# DMASS_BCDMA_0_DMASS_BCDMA_0_BCDMA_FLOW_48300000h register map
Vendor: Texas Instruments
Peripheral module from a debugger description file (folder am62L).
Registers are 32-bit, read-write, reset 0x0 unless marked. A register's access mark holds for its fields unless they carry their own. Offsets are as the file gives them; lines under a group give offsets from that group; [hi:lo] are bit positions; {n}, {i} and the like mark numbered series; 'fields as' and 'values as' point back to an identical list; <NAME> marks a mode.

## DMASS_BCDMA_0_BCDMA_FLOW
0x00 DMASS_BCDMA_0_BCDMA_FLOW_FLOW_resrc_j reset 0x80000000 — The Flow Resource Register contains the alias to real time register. A write to this register will reset the associated ring to clear the occupancies and reset the pointers.
  [31] ALIAS — Allow the Ring Address and Size Registers to appear in the Ring Real-Time region to allow for the ring to be placed and sized by the user process. Reset Source: rst_mod_g_rst_n
0x40 DMASS_BCDMA_0_BCDMA_FLOW_FLOW_ba_lo_j — The Ring Base Address Lo Register contains the 32 LSBs of the base address for the ring which is used to hand off pending work for the channel from the Host. The base address must be aligned to 0x8. A write to this register will reset the associated ring to clear the occupancies and reset the pointers.
  [31:0] ADDR_LO — Ring base address (LSBs) Reset Source: rst_mod_g_rst_n
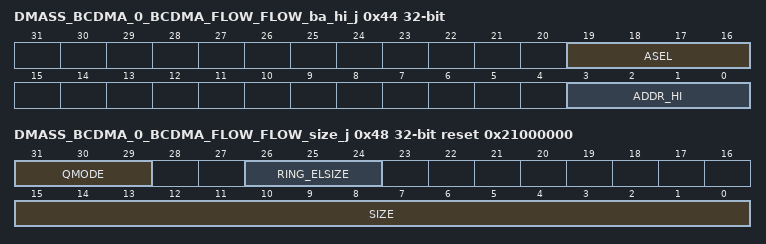
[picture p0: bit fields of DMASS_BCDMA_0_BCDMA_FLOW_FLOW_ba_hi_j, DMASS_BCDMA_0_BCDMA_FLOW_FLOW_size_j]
0x44 DMASS_BCDMA_0_BCDMA_FLOW_FLOW_ba_hi_j — The Ring Base Address Hi Register contains the 16 MSBs of the base address for the ring which is used to hand off pending work for the channel from the Host. The base address must be aligned to 0x8. A write to this register will reset the associated ring to clear the occupancies and reset the pointers.
  [19:16] ASEL — Ring base address select Reset Source: rst_mod_g_rst_n
  [3:0] ADDR_HI — Ring base address (MSBs) Reset Source: rst_mod_g_rst_n
0x48 DMASS_BCDMA_0_BCDMA_FLOW_FLOW_size_j access not given reset 0x21000000 — The Ring Size Register contains the element count for the ring which is used to hand off pending work for the channel from the Host. A write to this register will reset the associated ring to clear the occupancies and reset the pointers.
  [31:29] QMODE — Defines the mode for this ring or queue. 1 exposed ring mode with dual queues (forward/reverse) for SW direct access (access R/NA)
  [26:24] RING_ELSIZE — This field is hardcode as 1 = 8 bytes. Reset Source: rst_mod_g_rst_n (access R/NA)
  [15:0] SIZE rw — This field configures the size of the ring in elements. Reset Source: rst_mod_g_rst_n
